# RA6M1 register map
Vendor: Renesas Electronics Corporation; Series: RA6; File version: 1.2
CPU: CM4 r0p1, little endian, MPU, FPU, VTOR, 4 interrupt priority bits
Registers are 8-bit, read-write, reset 0x0 unless marked. A register's access mark holds for its fields unless they carry their own. Offsets are from the block's base; [hi:lo] are bit positions; {n}, {i} and the like mark numbered series; 'fields as' and 'values as' point back to an identical list.

## IRDA — Infrared Data Association
Base 0x40070F00
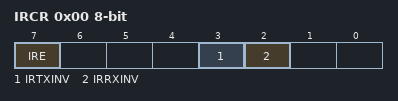
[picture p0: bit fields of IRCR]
0x00 IRCR — IrDA Control Register
  [7] IRE — IrDA Enable
    0=Serial I/O pins are used for normal serial communication; 1=Serial I/O pins are used for IrDA data communication
  [3] IRTXINV — IRTXD Polarity Switching
    0=Data to be transmitted is output to IRTXD as is; 1=Data to be transmitted is output to IRTXD after the polarity is inverted
  [2] IRRXINV — IRRXD Polarity Switching
    0=IRRXD input is used as received data as is; 1=IRRXD input is used as received data after the polarity is inverted

## SRCRAM — Sampling Rate Converter RAM
Base 0x40048000
{0x0+4i} SRCFCTR[{i}] (i=0..5551) 32-bit (reset mask 0xFFC00000) — Filter Coefficient Table [{i}]
  [21:0] SRCFCOE — Stores a filter coefficient value.

## DBG — Debug Function
Base 0x4001B000
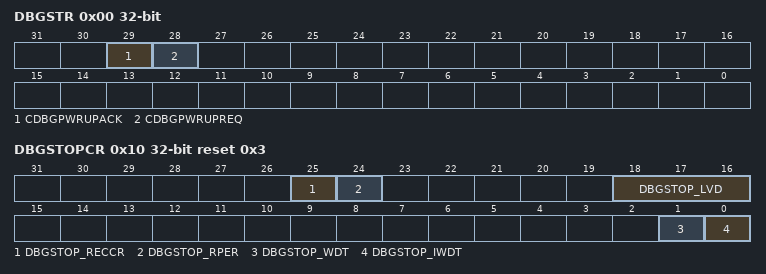
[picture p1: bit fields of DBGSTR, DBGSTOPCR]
0x00 DBGSTR 32-bit ro — Debug Status Register
  [29] CDBGPWRUPACK — Debug power-up acknowledge
    0=Debug power-up request is not acknowledged; 1=Debug power-up request is acknowledged
  [28] CDBGPWRUPREQ — Debug power-up request
    0=OCD is not requesting debug power-up; 1=OCD is requesting debug power-up
0x10 DBGSTOPCR 32-bit reset 0x3 — Debug Stop Control Register
  [25] DBGSTOP_RECCR — Mask bit for RAM ECC error reset/interrupt
    0=Enable RAM ECC error reset/interrupt; 1=Mask RAM ECC error reset/interrupt
  [24] DBGSTOP_RPER — Mask bit for RAM parity error reset/interrupt
    0=Enable RAM parity error reset/interrupt; 1=Mask RAM parity error reset/interrupt
  [18:16] DBGSTOP_LVD — b18: Mask bit for LVD2 reset/interrupt (0:enable / 1:Mask)b17: Mask bit for LVD1 reset/interrupt (0:enable / 1:Mask)b16: Mask bit for LVD0 reset (0:enable / 1:Mask)
  [1] DBGSTOP_WDT — Mask bit for WDT reset/interrupt
    0=Mask WDT reset/interrupt; 1=Enable WDT reset
  [0] DBGSTOP_IWDT — Mask bit for IWDT reset/interrupt
    0=Mask IWDT reset/interrupt; 1=Enable IWDT reset
0x20 TRACECTR 32-bit — Trace Control Register
  [31] ENETBFULL — Enable bit for halt request by ETB full
    0=ETB full does not cause CPU halt; 1=ETB full cause CPU halt

## DMAC0 — Direct memory access controller 0
Base 0x40005000
Same registers: DMAC1 0x40005040, DMAC2 0x40005080, DMAC3 0x400050C0, DMAC4 0x40005100, DMAC5 0x40005140, DMAC6 0x40005180, DMAC7 0x400051C0
0x00 DMSAR 32-bit — DMA Source Address Register
  [31:0] DMSAR — Specifies the transfer source start address.
0x04 DMDAR 32-bit — DMA Destination Address Register
  [31:0] DMDAR — Specifies the transfer destination start address.
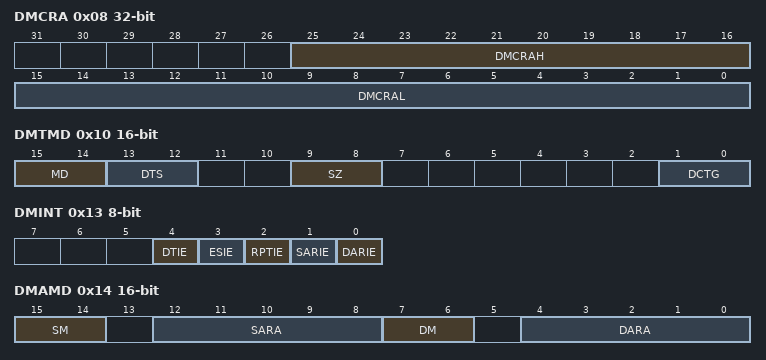
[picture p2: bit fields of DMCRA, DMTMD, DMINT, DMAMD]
0x08 DMCRA 32-bit — DMA Transfer Count Register
  [25:16] DMCRAH — Upper bits of transfer count
  [15:0] DMCRAL — Lower bits of transfer count
0x0C DMCRB 16-bit — DMA Block Transfer Count Register
  [15:0] DMCRB — Specifies the number of block transfer operations or repeat transfer operations.
    0=65,536 blocks; other=others (DMCRB blocks)
0x10 DMTMD 16-bit — DMA Transfer Mode Register
  [15:14] MD — Transfer Mode Select
    0=Normal transfer; 1=Repeat transfer; 2=Block transfer; 3=Setting prohibited
  [13:12] DTS — Repeat Area Select
    0=Specify destination as the repeat area or block area; 1=Specify source as the repeat area or block area; 2=Do not specify repeat area or block area; 3=Setting prohibited
  [9:8] SZ — Transfer Data Size Select
    0=8 bits; 1=16 bits; 2=32 bits; 3=Setting prohibited
  [1:0] DCTG — Transfer Request Source Select
    0=Software; 1=Interrupts from peripheral modules or external interrupt input pins; other=others (Setting prohibited)
0x13 DMINT — DMA Interrupt Setting Register
  [all] fields
    0=Disable; 1=Enable
  [4] DTIE — Transfer End Interrupt Enable
  [3] ESIE — Transfer Escape End Interrupt Enable
  [2] RPTIE — Repeat Size End Interrupt Enable
  [1] SARIE — Source Address Extended Repeat Area Overflow Interrupt Enable
  [0] DARIE — Destination Address Extended Repeat Area Overflow Interrupt Enable
0x14 DMAMD 16-bit — DMA Address Mode Register
  [15:14] SM — Source Address Update Mode
    0=Fixed address; 1=Offset addition; 2=Incremented address; 3=Decremented address
  [12:8] SARA — Source Address Extended Repeat Area Specifies the extended repeat area on the source address. For details on the settings.
  [7:6] DM — Destination Address Update Mode
    values as SM
  [4:0] DARA — Destination Address Extended Repeat Area Specifies the extended repeat area on the destination address. For details on the settings.
0x18 DMOFR 32-bit — DMA Offset Register
  [31:0] DMOFR — Specifies the offset when offset addition is selected as the address update mode for transfer source or destination.
0x1C DMCNT — DMA Transfer Enable Register
  [0] DTE read-modifies — DMA Transfer Enable
    0=Disable; 1=Enable
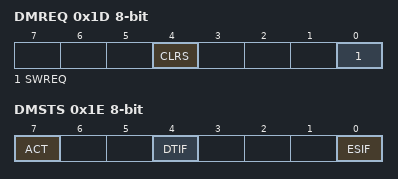
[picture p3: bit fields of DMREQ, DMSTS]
0x1D DMREQ — DMA Software Start Register
  [4] CLRS — DMA Software Start Bit Auto Clear Select
    0=Clear SWREQ bit after DMA transfer is started by software; 1=Do not clear SWREQ bit after DMA transfer is started by software
  [0] SWREQ read-modifies — DMA Software Start
    0=Do not request DMA transfer; 1=Request DMA transfer
0x1E DMSTS — DMAC Module Activation Register
  [7] ACT ro — DMA Active Flag
    0=DMAC operation is suspended; 1=DMAC is operating
  [4] DTIF write-0-clears read-modifies — Transfer End Interrupt Flag
    0=No interrupt occurred; 1=Interrupt occurred
  [0] ESIF write-0-clears read-modifies — Transfer Escape End Interrupt Flag
    0=A transfer escape end interrupt has not been generated; 1=A transfer escape end interrupt has been generated
